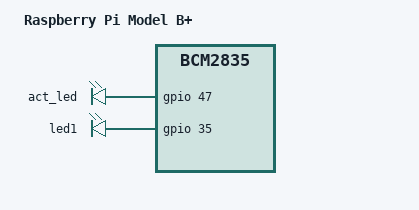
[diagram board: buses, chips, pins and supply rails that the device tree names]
/dts-v1/;
/include/ "bcm2835-rpi.dtsi"

/ {
	compatible = "raspberrypi,model-b-plus", "brcm,bcm2835";
	model = "Raspberry Pi Model B+";
};

&gpio {
	i2s_pins: i2s {
		brcm,pins = <18 19 20 21>;
		brcm,function = <4>; /* alt0 */
	};
};

&i2s {
	#sound-dai-cells = <0>;
	pinctrl-names = "default";
	pinctrl-0 = <&i2s_pins>;
};

&act_led {
	gpios = <&gpio 47 0>;
};

&leds {
	pwr_led: pwr {
		label = "led1";
		linux,default-trigger = "input";
		gpios = <&gpio 35 0>;
	};
};

/ {
	__overrides__ {
		act_led_gpio = <&act_led>,"gpios:4";
		act_led_activelow = <&act_led>,"gpios:8";

		pwr_led_gpio = <&pwr_led>,"gpios:4";
		pwr_led_activelow = <&pwr_led>,"gpios:8";
		pwr_led_trigger = <&pwr_led>,"linux,default-trigger";
	};
};
